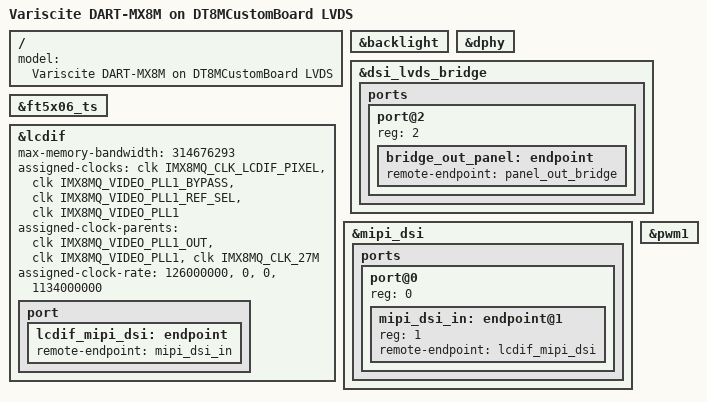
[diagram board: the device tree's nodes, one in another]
// SPDX-License-Identifier: (GPL-2.0 OR MIT)
/*
 * Device tree to support LVDS LCDIF on DART-MX8M
 *
 * Copyright 2017 NXP
 * Copyright 2018-2024 Variscite Ltd.
 */

#include "imx8mq-var-dart-dt8mcustomboard.dtsi"
#include "imx8mq-var-dart-lvds-panel.dtsi"

/ {
	model = "Variscite DART-MX8M on DT8MCustomBoard LVDS";
};

&backlight {
	status = "okay";
};

&dphy {
	status = "okay";
};

&dsi_lvds_bridge {
	status = "okay";

	ports {
		#address-cells = <1>;
		#size-cells = <0>;

		port@2 {
			reg = <2>;
			bridge_out_panel: endpoint {
				remote-endpoint = <&panel_out_bridge>;
			};
		};
	};
};

&ft5x06_ts {
	status = "okay";
};

&lcdif {
	status = "okay";
	max-memory-bandwidth = <314676293>; /* 1280x1024-32@60 */

	assigned-clocks = <&clk IMX8MQ_CLK_LCDIF_PIXEL>,
			  <&clk IMX8MQ_VIDEO_PLL1_BYPASS>,
			  <&clk IMX8MQ_VIDEO_PLL1_REF_SEL>,
			  <&clk IMX8MQ_VIDEO_PLL1>;
	assigned-clock-parents = <&clk IMX8MQ_VIDEO_PLL1_OUT>,
				 <&clk IMX8MQ_VIDEO_PLL1>,
				 <&clk IMX8MQ_CLK_27M>;
	assigned-clock-rate = <126000000>, <0>, <0>, <1134000000>;

        port {
                lcdif_mipi_dsi: endpoint {
                        remote-endpoint = <&mipi_dsi_in>;
                };
        };

};

&mipi_dsi {
        status = "okay";

        ports {
                #address-cells = <1>;
                #size-cells = <0>;

                port@0 {
                        #address-cells = <1>;
                        #size-cells = <0>;
                        reg = <0>;

                        mipi_dsi_in: endpoint@1 {
                                reg = <1>;
                                remote-endpoint = <&lcdif_mipi_dsi>;
                        };
                };
        };
};

&pwm1 {
	status = "okay";
};
